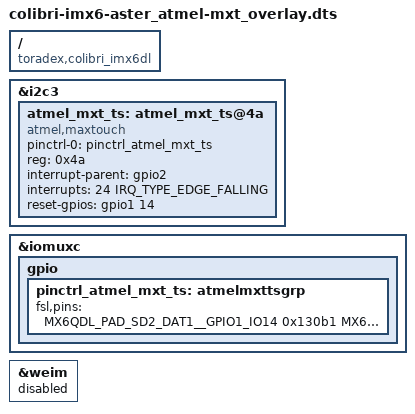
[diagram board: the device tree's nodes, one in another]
// Atmel touchscreen for the 7inch capacitive display orderable at Toradex. Use this devicetree on the Aster board.

/dts-v1/;
/plugin/;

#include <dt-bindings/gpio/gpio.h>
#include <dt-bindings/interrupt-controller/irq.h>
#include <imx6dl-pinfunc.h>

/ {
	compatible = "toradex,colibri_imx6dl";
};

&i2c3 {
	#address-cells = <1>;
	#size-cells = <0>;

	atmel_mxt_ts: atmel_mxt_ts@4a {
		pinctrl-names = "default";
		pinctrl-0 = <&pinctrl_atmel_mxt_ts>;
		compatible = "atmel,maxtouch";
		reg = <0x4a>;
		interrupt-parent = <&gpio2>;
		interrupts = <24 IRQ_TYPE_EDGE_FALLING>;
		reset-gpios = <&gpio1 14 GPIO_ACTIVE_HIGH>;
	};
};

&iomuxc {
	gpio {
		pinctrl_atmel_mxt_ts: atmelmxttsgrp {
			fsl,pins = <
				MX6QDL_PAD_SD2_DAT1__GPIO1_IO14	0x130b1	/* SODIMM_106 */
				MX6QDL_PAD_EIM_CS1__GPIO2_IO24	0x130b1	/* SODIMM_107 */
			>;
		};
	};
};

&weim {
	status = "disabled";
};
